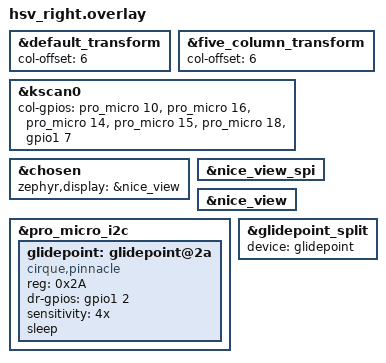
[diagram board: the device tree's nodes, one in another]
/*
 * Copyright (c) 2022 The ZMK Contributors
 *
 * SPDX-License-Identifier: MIT
 */

#include "hsv.dtsi"

&default_transform {
  col-offset = <6>;
};

&five_column_transform {
    col-offset = <6>;
};

&kscan0 {
  col-gpios
    = <&pro_micro 10 GPIO_ACTIVE_HIGH>
    , <&pro_micro 16 GPIO_ACTIVE_HIGH>
    , <&pro_micro 14 GPIO_ACTIVE_HIGH>
    , <&pro_micro 15 GPIO_ACTIVE_HIGH>
    , <&pro_micro 18 GPIO_ACTIVE_HIGH>
    , <&gpio1 7 GPIO_ACTIVE_HIGH>
    ;
};

&chosen {
  zephyr,display = &nice_view;
};

&nice_view_spi {
  status = "okay";
};

&nice_view {
  status = "okay";
};

&pro_micro_i2c {
    status = "okay";

    glidepoint: glidepoint@2a {
        compatible = "cirque,pinnacle";
        reg = <0x2A>;
        status = "okay";
        dr-gpios = <&gpio1 2 (GPIO_ACTIVE_HIGH)>;

        sensitivity = "4x";
        sleep;
    };
};

&glidepoint_split {
    device = <&glidepoint>;

    // optional input processor
    // input-processor = <>
};
